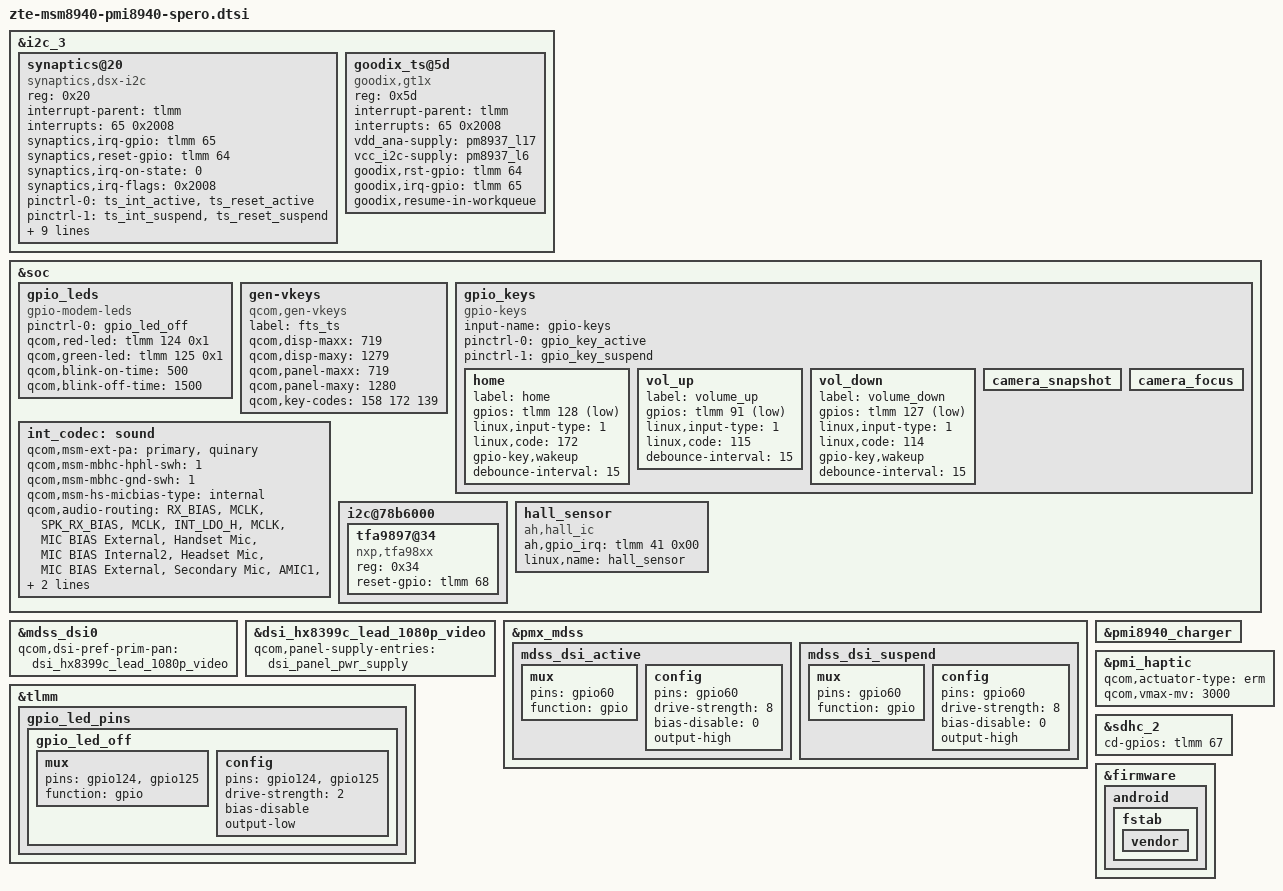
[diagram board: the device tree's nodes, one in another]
/*
 * Copyright (c) 2016, The Linux Foundation. All rights reserved.
 *
 * This program is free software; you can redistribute it and/or modify
 * it under the terms of the GNU General Public License version 2 and
 * only version 2 as published by the Free Software Foundation.
 *
 * This program is distributed in the hope that it will be useful,
 * but WITHOUT ANY WARRANTY; without even the implied warranty of
 * MERCHANTABILITY or FITNESS FOR A PARTICULAR PURPOSE.  See the
 * GNU General Public License for more details.
 */

#include "dsi-panel-hx8399c-lead-1080p-video.dtsi" /*add by yujianhua for V8*/

 /* add by wkh begin*/
&i2c_3 { /* BLSP1 QUP3 */
	synaptics@20 {
		compatible = "synaptics,dsx-i2c";
		reg = <0x20>;
		interrupt-parent = <&tlmm>;
		interrupts = <65 0x2008>;
		/*vdd-supply = <&pm8917_l17>;*/
		/*vddio-supply = <&pm8917_l6>;*/
		/*synaptics,pwr-reg-name = "vdd";*/
		/*synaptics,bus-reg-name = "vddio";*/
		synaptics,irq-gpio = <&tlmm 65 0x2008>;
		synaptics,reset-gpio = <&tlmm 64 0x0>;
		synaptics,irq-on-state = <0>;
		synaptics,irq-flags = <0x2008>; /* IRQF_ONESHOT | IRQF_TRIGGER_LOW */
		/* pins used by touchscreen */
		pinctrl-names = "pmx_ts_active","pmx_ts_suspend","pmx_ts_release";
		pinctrl-0 = <&ts_int_active &ts_reset_active>;
		pinctrl-1 = <&ts_int_suspend &ts_reset_suspend>;
		pinctrl-2 = <&ts_release>;
		synaptics,power-delay-ms = <200>;
		synaptics,reset-delay-ms = <200>;
		synaptics,reset-on-state = <0>;
		synaptics,reset-active-ms = <20>;
		synaptics,display-coords = <0 0 719 1279>;
		synaptics,panel-coords = <0 0 719 1280>;
		synaptics,button-map = <158 172 139>;
		/* uncomment and update line below as appropriate if there are 0D buttons */
		synaptics,cap-button-codes = <158 172 139>;
		/* uncomment and update lines below as appropriate if there are virtual buttons */
		/* synaptics,vir-button-codes = <102 100 900 100 60 158 300 900 100 60>; */
		/* synaptics,max-y-for-2d = <800>; */
	};
	goodix_ts@5d {
		compatible = "goodix,gt1x";
		reg = <0x5d>;
		interrupt-parent = <&tlmm>;
		interrupts = <65 0x2008>;
		vdd_ana-supply = <&pm8937_l17>;
		vcc_i2c-supply = <&pm8937_l6>;
		goodix,rst-gpio = <&tlmm 64 0x0>;
		goodix,irq-gpio = <&tlmm 65 0x2008>;
		goodix,resume-in-workqueue;
	};
};
/*  end by wkh */

&soc {
	/* added by zte_fangjun for color_led,start */
	gpio_leds {
		compatible = "gpio-modem-leds";
		status = "okay";
		pinctrl-names = "default";
		pinctrl-0 = <&gpio_led_off>;
		qcom,red-led = <&tlmm 124 0x1>;
		qcom,green-led = <&tlmm 125 0x1>;
		/*qcom,trickle_red-led = <&tlmm 3 0x1>;*/
		qcom,blink-on-time = <500>;
		qcom,blink-off-time = <1500>;
	};
	/* added by zte_sw_fangjun for color_led,end */
	gen-vkeys {
		compatible = "qcom,gen-vkeys";
		label = "fts_ts";
		qcom,disp-maxx = <719>;
		qcom,disp-maxy = <1279>;
		qcom,panel-maxx = <719>;
		qcom,panel-maxy = <1280>;
		qcom,key-codes = <158 172 139>;
	};
	gpio_keys {
		compatible = "gpio-keys";
		input-name = "gpio-keys";
		pinctrl-names = "tlmm_gpio_key_active","tlmm_gpio_key_suspend";
		pinctrl-0 = <&gpio_key_active>;
		pinctrl-1 = <&gpio_key_suspend>;
		home {
			label = "home";
			gpios = <&tlmm 128 0x1>;
			linux,input-type = <1>;
			linux,code = <172>;
			gpio-key,wakeup;
			debounce-interval = <15>;
		};
		vol_up {
			label = "volume_up";
			gpios = <&tlmm 91 0x1>;
			linux,input-type = <1>;
			linux,code = <115>;
			debounce-interval = <15>;
		};
		vol_down {
			label = "volume_down";
			gpios = <&tlmm 127 0x1>;
			linux,input-type = <1>;
			linux,code = <114>;
			gpio-key,wakeup;
			debounce-interval = <15>;
		};
		camera_snapshot {
		/delete-property/ label;
		/delete-property/ gpios;
		/delete-property/ linux,input-type;
		/delete-property/ linux,code;
		/delete-property/ debounce-interval;
		};
		camera_focus {
		/delete-property/ label;
		/delete-property/ gpios;
		/delete-property/ linux,input-type;
		/delete-property/ linux,code;
		/delete-property/ debounce-interval;
		};
	};
};

/*zteadd by yujianhua for lcm F10 start*/
&mdss_dsi0 {
	qcom,dsi-pref-prim-pan = <&dsi_hx8399c_lead_1080p_video>;
	/delete-property/ qcom,platform-enable-gpio;
	/delete-property/ qcom,platform-bklight-en-gpio;
};
/*zteadd by yujianhua for lcm F10 end*/

/*zteadd by yujianhua for lcm F10 start*/
&dsi_hx8399c_lead_1080p_video {
	qcom,panel-supply-entries = <&dsi_panel_pwr_supply>;
};
/*zteadd by yujianhua for lcm F10 end*/

&i2c_3 { /* BLSP1 QUP3 */
	status = "ok";
};
/*zteadd by yujianhua for lcm F10 reset pin start*/
&pmx_mdss {
	mdss_dsi_active: mdss_dsi_active {
		mux {
			pins = "gpio60";
			function = "gpio";
		};

		config {
			pins = "gpio60";
			drive-strength = <8>; /* 8 mA */
			bias-disable = <0>; /* no pull */
			output-high;
		};
	};
	mdss_dsi_suspend: mdss_dsi_suspend {
		mux {
			pins = "gpio60";
			function = "gpio";
		};

		config {
			pins = "gpio60";
			/*zteadd by yujianhua for F10 reset high state insleepmode*/
			drive-strength = <8>; /* 8 mA */
			bias-disable = <0>; /* no pull */
			output-high;
			/*zteadd by yujianhua for F10 reset high state insleepmode end*/
		};
	};
};
/*zteadd by yujianhua for lcm F10 reset pin end*/
&soc {
	int_codec: sound {
		qcom,msm-ext-pa = "primary","quinary";
		qcom,msm-mbhc-hphl-swh = <1>;
		qcom,msm-mbhc-gnd-swh = <1>;
		qcom,msm-hs-micbias-type = "internal";
		qcom,audio-routing =
			"RX_BIAS", "MCLK",
			"SPK_RX_BIAS", "MCLK",
			"INT_LDO_H", "MCLK",
			"MIC BIAS External", "Handset Mic",
			"MIC BIAS Internal2", "Headset Mic",
			"MIC BIAS External", "Secondary Mic",
			"AMIC1", "MIC BIAS External",
			"AMIC2", "MIC BIAS Internal2",
			"AMIC3", "MIC BIAS External";
			/* WSA_SPK OUT", "VDD_WSA_SWITCH", */
			/* "SpkrMono WSA_IN", "WSA_SPK OUT"; */

			/delete-property/ qcom,hdmi-dba-codec-rx;
	};
	i2c@78b6000 {
	/*zte weiguohua add it for nxp smart pa chip*/
		tfa9897@34 {
			compatible = "nxp,tfa98xx";
			reg = <0x34>;
			reset-gpio = <&tlmm 68 0x0>;
		};
	/*zte weiguohua add it for nxp smart pa chip*/
	};

	hall_sensor {
		compatible = "ah,hall_ic";
		ah,gpio_irq = <&tlmm 41 0x00>;
		linux,name = "hall_sensor";
	};
};
/* added by zte_fangjun for color_led,start */
&tlmm {
	gpio_led_pins {
		gpio_led_off: gpio_led_off {
			mux {
				pins = "gpio124", "gpio125";
				function = "gpio";
			};

			config {
				pins = "gpio124", "gpio125";
				drive-strength = <2>;
				bias-disable;
				output-low;
			};
		};
	};
};
/* added by zte_fangjun for color_led,end */
&pmi8940_charger {
	/delete-property/ qcom,chg-led-sw-controls;
	/delete-property/ qcom,chg-led-support;
};
&pmi_haptic {
	qcom,actuator-type = "erm";
	qcom,vmax-mv = <3000>;
};
/*zteadd by yangshentao10176221 for F10 SD cd pin start*/
&sdhc_2 {
	cd-gpios = <&tlmm 67 0x0>;
};
/*zteadd by yangshentao10176221 for F10 SD cd pin end*/

/*zte add by chenwei10196163 for P840F10 compatible with Android N start*/
&firmware {
	android {
		fstab {
			vendor {
				status = "ok";
			};
		};
	};
};
/*zte add by chenwei10196163 for P840F10 compatible with Android N end*/

